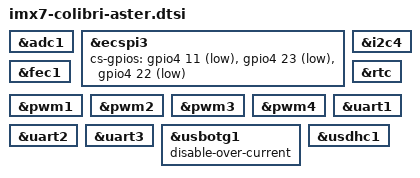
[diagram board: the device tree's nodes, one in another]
&adc1 {
	status = "okay";
};
&ecspi3 {
	cs-gpios = <
		&gpio4 11 GPIO_ACTIVE_LOW  
		&gpio4 23 GPIO_ACTIVE_LOW  
		&gpio4 22 GPIO_ACTIVE_LOW  
	>;
	status = "okay";
};
&fec1 {
	status = "okay";
};
&i2c4 {
	status = "okay";
};
&pwm1 {
	status = "okay";
};
&pwm2 {
	status = "okay";
};
&pwm3 {
	status = "okay";
};
&pwm4 {
	status = "okay";
};
&rtc {
	status = "okay";
};
&uart1 {
	status = "okay";
};
&uart2 {
	status = "okay";
};
&uart3 {
	status = "okay";
};
&usbotg1 {
	disable-over-current;
	status = "okay";
};
&usdhc1 {
	status = "okay";
};
